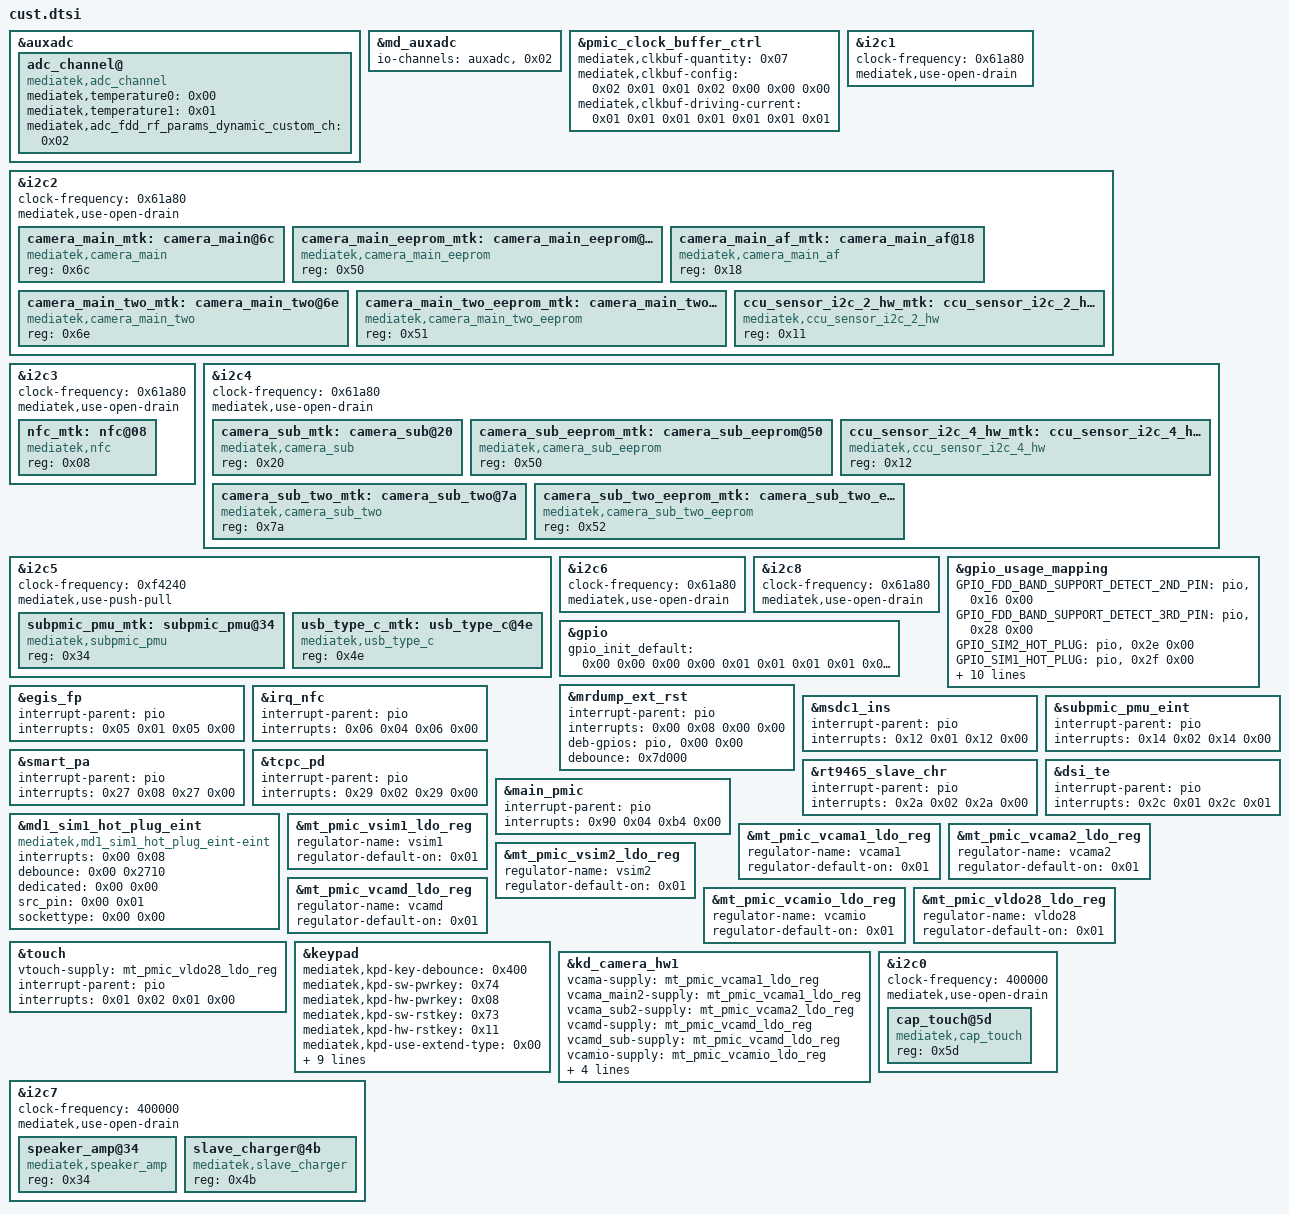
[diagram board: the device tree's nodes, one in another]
/*
 * cust.dtsi - reconstructed from stock dtbo (project 2167A / realme C25s)
 * Generated from stock boot image dtbo.img
 */

&auxadc {

	adc_channel@ {
		compatible = "mediatek,adc_channel";
		mediatek,temperature0 = <0x00>;
		mediatek,temperature1 = <0x01>;
		mediatek,adc_fdd_rf_params_dynamic_custom_ch = <0x02>;
		status = "okay";
	};
};

&md_auxadc {
	io-channels = <&auxadc>, <0x02>;
};

&pmic_clock_buffer_ctrl {
	mediatek,clkbuf-quantity = <0x07>;
	mediatek,clkbuf-config = <0x02 0x01 0x01 0x02 0x00 0x00 0x00>;
	mediatek,clkbuf-driving-current = <0x01 0x01 0x01 0x01 0x01 0x01 0x01>;
	status = "okay";
};

&i2c1 {
	#address-cells = <0x01>;
	#size-cells = <0x00>;
	clock-frequency = <0x61a80>;
	mediatek,use-open-drain;
};

&i2c2 {
	#address-cells = <0x01>;
	#size-cells = <0x00>;
	clock-frequency = <0x61a80>;
	mediatek,use-open-drain;

	camera_main_mtk: camera_main@6c {
		compatible = "mediatek,camera_main";
		reg = <0x6c>;
		status = "okay";
	};

	camera_main_eeprom_mtk: camera_main_eeprom@50 {
		compatible = "mediatek,camera_main_eeprom";
		reg = <0x50>;
		status = "okay";
	};

	camera_main_af_mtk: camera_main_af@18 {
		compatible = "mediatek,camera_main_af";
		reg = <0x18>;
		status = "okay";
	};

	camera_main_two_mtk: camera_main_two@6e {
		compatible = "mediatek,camera_main_two";
		reg = <0x6e>;
		status = "okay";
	};

	camera_main_two_eeprom_mtk: camera_main_two_eeprom@51 {
		compatible = "mediatek,camera_main_two_eeprom";
		reg = <0x51>;
		status = "okay";
	};

	ccu_sensor_i2c_2_hw_mtk: ccu_sensor_i2c_2_hw@11 {
		compatible = "mediatek,ccu_sensor_i2c_2_hw";
		reg = <0x11>;
		status = "okay";
	};
};

&i2c3 {
	#address-cells = <0x01>;
	#size-cells = <0x00>;
	clock-frequency = <0x61a80>;
	mediatek,use-open-drain;

	nfc_mtk: nfc@08 {
		compatible = "mediatek,nfc";
		reg = <0x08>;
		status = "okay";
	};
};

&i2c4 {
	#address-cells = <0x01>;
	#size-cells = <0x00>;
	clock-frequency = <0x61a80>;
	mediatek,use-open-drain;

	camera_sub_mtk: camera_sub@20 {
		compatible = "mediatek,camera_sub";
		reg = <0x20>;
		status = "okay";
	};

	camera_sub_eeprom_mtk: camera_sub_eeprom@50 {
		compatible = "mediatek,camera_sub_eeprom";
		reg = <0x50>;
		status = "okay";
	};

	ccu_sensor_i2c_4_hw_mtk: ccu_sensor_i2c_4_hw@12 {
		compatible = "mediatek,ccu_sensor_i2c_4_hw";
		reg = <0x12>;
		status = "okay";
	};

	camera_sub_two_mtk: camera_sub_two@7a {
		compatible = "mediatek,camera_sub_two";
		reg = <0x7a>;
		status = "okay";
	};

	camera_sub_two_eeprom_mtk: camera_sub_two_eeprom@52 {
		compatible = "mediatek,camera_sub_two_eeprom";
		reg = <0x52>;
		status = "okay";
	};
};

&i2c5 {
	#address-cells = <0x01>;
	#size-cells = <0x00>;
	clock-frequency = <0xf4240>;
	mediatek,use-push-pull;

	subpmic_pmu_mtk: subpmic_pmu@34 {
		compatible = "mediatek,subpmic_pmu";
		reg = <0x34>;
		status = "okay";
	};

	usb_type_c_mtk: usb_type_c@4e {
		compatible = "mediatek,usb_type_c";
		reg = <0x4e>;
		status = "okay";
	};
};

&i2c6 {
	#address-cells = <0x01>;
	#size-cells = <0x00>;
	clock-frequency = <0x61a80>;
	mediatek,use-open-drain;
};

&i2c8 {
	#address-cells = <0x01>;
	#size-cells = <0x00>;
	clock-frequency = <0x61a80>;
	mediatek,use-open-drain;
};

&gpio_usage_mapping {
	GPIO_FDD_BAND_SUPPORT_DETECT_2ND_PIN = <&pio>, <0x16 0x00>;
	GPIO_FDD_BAND_SUPPORT_DETECT_3RD_PIN = <&pio>, <0x28 0x00>;
	GPIO_SIM2_HOT_PLUG = <&pio>, <0x2e 0x00>;
	GPIO_SIM1_HOT_PLUG = <&pio>, <0x2f 0x00>;
	GPIO_FDD_BAND_SUPPORT_DETECT_1ST_PIN = <&pio>, <0x5b 0x00>;
	GPIO_FDD_BAND_SUPPORT_DETECT_4TH_PIN = <&pio>, <0x5c 0x00>;
	GPIO_SIM2_SIO = <&pio>, <0x9b 0x00>;
	GPIO_SIM2_SRST = <&pio>, <0x9c 0x00>;
	GPIO_SIM2_SCLK = <&pio>, <0x9d 0x00>;
	GPIO_SIM1_SCLK = <&pio>, <0xac 0x00>;
	GPIO_SIM1_SRST = <&pio>, <0xad 0x00>;
	GPIO_SIM1_SIO = <&pio>, <0xae 0x00>;
};

&gpio {
	gpio_init_default = <0x00 0x00 0x00 0x00 0x01 0x01 0x01 0x01 0x00 0x00 0x00 0x01 0x01 0x01 0x02 0x00 0x00 0x00 0x01 0x00 0x01 0x03 0x00 0x00 0x00 0x01 0x00 0x01 0x04 0x00 0x01 0x00 0x01 0x00 0x00 0x05 0x00 0x00 0x00 0x01 0x00 0x00 0x06 0x00 0x00 0x00 0x01 0x00 0x00 0x07 0x00 0x00 0x00 0x01 0x00 0x00 0x08 0x07 0x00 0x00 0x01 0x00 0x00 0x09 0x00 0x00 0x00 0x01 0x00 0x00 0x0a 0x00 0x00 0x00 0x01 0x01 0x00 0x0b 0x01 0x00 0x00 0x01 0x00 0x00 0x0c 0x02 0x00 0x00 0x01 0x00 0x00 0x0d 0x02 0x00 0x00 0x01 0x00 0x00 0x0e 0x02 0x01 0x00 0x00 0x00 0x00 0x0f 0x02 0x01 0x00 0x00 0x00 0x00 0x10 0x02 0x01 0x00 0x00 0x00 0x00 0x11 0x00 0x00 0x00 0x00 0x00 0x01 0x12 0x00 0x00 0x00 0x01 0x01 0x01 0x13 0x00 0x01 0x00 0x01 0x00 0x01 0x14 0x00 0x00 0x00 0x00 0x00 0x01 0x15 0x00 0x01 0x00 0x00 0x00 0x00 0x16 0x00 0x00 0x00 0x01 0x00 0x00 0x17 0x00 0x01 0x01 0x00 0x00 0x00 0x18 0x05 0x00 0x00 0x01 0x00 0x00 0x19 0x02 0x01 0x01 0x00 0x00 0x00 0x1a 0x02 0x01 0x00 0x01 0x00 0x00 0x1b 0x02 0x01 0x00 0x00 0x00 0x00 0x1c 0x02 0x00 0x00 0x01 0x00 0x00 0x1d 0x00 0x01 0x00 0x00 0x00 0x00 0x1e 0x00 0x01 0x00 0x00 0x00 0x00 0x1f 0x00 0x00 0x00 0x01 0x00 0x00 0x20 0x07 0x01 0x00 0x00 0x00 0x00 0x21 0x07 0x00 0x00 0x01 0x00 0x00 0x22 0x07 0x00 0x00 0x01 0x00 0x00 0x23 0x07 0x00 0x00 0x01 0x00 0x00 0x24 0x02 0x01 0x00 0x00 0x00 0x00 0x25 0x02 0x01 0x00 0x00 0x00 0x00 0x26 0x00 0x00 0x00 0x01 0x01 0x00 0x27 0x00 0x00 0x00 0x01 0x01 0x01 0x28 0x00 0x00 0x00 0x01 0x00 0x00 0x29 0x00 0x00 0x00 0x01 0x01 0x01 0x2a 0x00 0x00 0x00 0x01 0x01 0x01 0x2b 0x01 0x01 0x00 0x00 0x00 0x00 0x2c 0x01 0x00 0x00 0x01 0x00 0x00 0x2d 0x00 0x01 0x00 0x00 0x00 0x00 0x2e 0x01 0x00 0x00 0x01 0x01 0x00 0x2f 0x01 0x00 0x00 0x01 0x01 0x00 0x30 0x01 0x00 0x00 0x01 0x01 0x01 0x31 0x01 0x00 0x00 0x01 0x01 0x01 0x32 0x01 0x00 0x00 0x01 0x01 0x01 0x33 0x01 0x00 0x00 0x01 0x01 0x01 0x34 0x01 0x00 0x00 0x01 0x00 0x00 0x35 0x00 0x01 0x00 0x00 0x00 0x00 0x36 0x00 0x01 0x00 0x01 0x00 0x00 0x37 0x01 0x00 0x00 0x01 0x00 0x00 0x38 0x01 0x00 0x00 0x01 0x00 0x00 0x39 0x01 0x00 0x00 0x01 0x00 0x00 0x3a 0x00 0x00 0x00 0x01 0x00 0x00 0x3b 0x01 0x00 0x00 0x01 0x00 0x00 0x3c 0x01 0x00 0x00 0x01 0x00 0x00 0x3d 0x01 0x00 0x00 0x01 0x00 0x00 0x3e 0x01 0x00 0x00 0x01 0x00 0x00 0x3f 0x01 0x00 0x00 0x01 0x00 0x00 0x40 0x01 0x00 0x00 0x01 0x00 0x00 0x41 0x01 0x00 0x00 0x01 0x00 0x00 0x42 0x01 0x00 0x00 0x01 0x00 0x00 0x43 0x01 0x00 0x00 0x01 0x00 0x00 0x44 0x01 0x00 0x00 0x01 0x00 0x00 0x45 0x01 0x00 0x00 0x01 0x00 0x00 0x46 0x01 0x00 0x00 0x01 0x00 0x00 0x47 0x01 0x00 0x00 0x01 0x00 0x00 0x48 0x01 0x00 0x00 0x01 0x00 0x00 0x49 0x01 0x00 0x00 0x01 0x00 0x00 0x4a 0x01 0x00 0x00 0x01 0x00 0x00 0x4b 0x01 0x00 0x00 0x01 0x00 0x00 0x4c 0x00 0x00 0x00 0x00 0x00 0x00 0x4d 0x01 0x00 0x00 0x01 0x00 0x00 0x4e 0x01 0x00 0x00 0x01 0x00 0x00 0x4f 0x00 0x00 0x00 0x01 0x00 0x00 0x50 0x00 0x00 0x00 0x01 0x00 0x00 0x51 0x02 0x00 0x00 0x01 0x01 0x01 0x52 0x01 0x00 0x00 0x01 0x01 0x01 0x53 0x01 0x00 0x00 0x01 0x01 0x01 0x54 0x02 0x00 0x00 0x01 0x01 0x01 0x55 0x02 0x00 0x00 0x01 0x00 0x00 0x56 0x02 0x01 0x00 0x00 0x00 0x00 0x57 0x02 0x01 0x00 0x00 0x00 0x00 0x58 0x02 0x01 0x00 0x00 0x00 0x00 0x59 0x01 0x00 0x00 0x01 0x01 0x01 0x5a 0x01 0x00 0x00 0x01 0x01 0x01 0x5b 0x00 0x00 0x00 0x01 0x00 0x00 0x5c 0x00 0x00 0x00 0x01 0x00 0x00 0x5d 0x01 0x00 0x00 0x01 0x01 0x00 0x5e 0x01 0x00 0x00 0x01 0x01 0x00 0x5f 0x01 0x00 0x00 0x01 0x01 0x00 0x60 0x01 0x01 0x00 0x00 0x00 0x00 0x61 0x00 0x01 0x00 0x00 0x00 0x00 0x62 0x00 0x01 0x00 0x00 0x00 0x00 0x63 0x01 0x01 0x00 0x00 0x00 0x00 0x64 0x01 0x01 0x00 0x00 0x00 0x00 0x65 0x00 0x01 0x00 0x00 0x00 0x00 0x66 0x00 0x01 0x00 0x00 0x00 0x00 0x67 0x01 0x00 0x00 0x01 0x01 0x01 0x68 0x01 0x00 0x00 0x01 0x01 0x01 0x69 0x01 0x00 0x00 0x01 0x01 0x01 0x6a 0x01 0x00 0x00 0x01 0x01 0x01 0x6b 0x00 0x01 0x00 0x00 0x00 0x00 0x6c 0x01 0x01 0x00 0x00 0x00 0x00 0x6d 0x00 0x01 0x00 0x00 0x00 0x00 0x6e 0x00 0x01 0x00 0x00 0x00 0x00 0x6f 0x01 0x01 0x00 0x00 0x00 0x00 0x70 0x00 0x01 0x00 0x00 0x00 0x00 0x71 0x00 0x00 0x00 0x01 0x00 0x00 0x72 0x00 0x00 0x00 0x01 0x00 0x00 0x73 0x00 0x00 0x00 0x01 0x00 0x00 0x74 0x00 0x00 0x00 0x01 0x00 0x00 0x75 0x00 0x00 0x00 0x01 0x00 0x00 0x76 0x00 0x00 0x00 0x01 0x00 0x00 0x77 0x00 0x00 0x00 0x01 0x00 0x00 0x78 0x00 0x00 0x00 0x01 0x00 0x00 0x79 0x00 0x00 0x00 0x01 0x00 0x00 0x86 0x01 0x00 0x00 0x01 0x00 0x01 0x87 0x01 0x01 0x00 0x00 0x00 0x00 0x88 0x01 0x01 0x00 0x00 0x00 0x00 0x89 0x01 0x01 0x00 0x00 0x00 0x00 0x8a 0x01 0x01 0x00 0x00 0x00 0x00 0x8b 0x01 0x01 0x00 0x00 0x00 0x00 0x8c 0x01 0x00 0x00 0x01 0x00 0x00 0x8d 0x01 0x00 0x00 0x01 0x00 0x00 0x8e 0x01 0x00 0x00 0x01 0x00 0x00 0x8f 0x01 0x00 0x00 0x01 0x00 0x00 0x90 0x01 0x00 0x00 0x01 0x00 0x00 0x91 0x01 0x01 0x00 0x00 0x00 0x00 0x92 0x01 0x01 0x00 0x00 0x00 0x00 0x93 0x01 0x01 0x00 0x00 0x00 0x00 0x94 0x01 0x01 0x00 0x00 0x00 0x00 0x95 0x01 0x01 0x00 0x00 0x00 0x00 0x96 0x04 0x00 0x00 0x01 0x01 0x00 0x97 0x04 0x01 0x00 0x00 0x00 0x00 0x98 0x00 0x01 0x00 0x01 0x01 0x00 0x99 0x00 0x01 0x00 0x00 0x00 0x00 0x9a 0x01 0x01 0x00 0x00 0x00 0x00 0x9b 0x01 0x00 0x00 0x01 0x01 0x00 0x9c 0x01 0x01 0x00 0x00 0x00 0x00 0x9d 0x01 0x01 0x00 0x00 0x00 0x00 0x9e 0x01 0x01 0x00 0x00 0x00 0x00 0x9f 0x00 0x01 0x00 0x00 0x00 0x00 0xa0 0x00 0x01 0x00 0x00 0x00 0x00 0xa1 0x01 0x00 0x00 0x01 0x01 0x01 0xa2 0x01 0x00 0x00 0x01 0x01 0x01 0xa3 0x01 0x00 0x00 0x01 0x01 0x01 0xa4 0x01 0x00 0x00 0x01 0x01 0x01 0xa5 0x00 0x01 0x00 0x00 0x00 0x00 0xa6 0x00 0x01 0x00 0x00 0x00 0x00 0xa7 0x01 0x00 0x00 0x01 0x00 0x00 0xa8 0x01 0x00 0x00 0x01 0x00 0x00 0xa9 0x00 0x01 0x00 0x00 0x00 0x00 0xaa 0x01 0x00 0x00 0x01 0x01 0x01 0xab 0x01 0x01 0x00 0x00 0x00 0x01 0xac 0x01 0x01 0x00 0x00 0x00 0x00 0xad 0x01 0x01 0x00 0x00 0x00 0x00 0xae 0x01 0x00 0x00 0x01 0x01 0x00 0xaf 0x01 0x00 0x00 0x01 0x01 0x01 0xb0 0x01 0x00 0x00 0x01 0x01 0x01 0xb2 0x00 0x01 0x00 0x00 0x00 0x00 0xb3 0x00 0x01 0x00 0x00 0x00 0x00 0xb4 0x00 0x00 0x00 0x01 0x00 0x00 0xb5 0x00 0x00 0x00 0x01 0x00 0x00 0xb6 0x00 0x00 0x00 0x01 0x00 0x00 0xb7 0x00 0x00 0x00 0x01 0x00 0x00 0xb8 0x00 0x00 0x00 0x01 0x00 0x00 0xb9 0x00 0x00 0x00 0x01 0x00 0x00 0xba 0x00 0x00 0x00 0x01 0x00 0x00>;
};

&mrdump_ext_rst {
	interrupt-parent = <&pio>;
	interrupts = <0x00 0x08 0x00 0x00>;
	deb-gpios = <&pio>, <0x00 0x00>;
	debounce = <0x7d000>;
	status = "okay";
};

&egis_fp {
	interrupt-parent = <&pio>;
	interrupts = <0x05 0x01 0x05 0x00>;
	status = "okay";
};

&irq_nfc {
	interrupt-parent = <&pio>;
	interrupts = <0x06 0x04 0x06 0x00>;
	status = "okay";
};

&msdc1_ins {
	interrupt-parent = <&pio>;
	interrupts = <0x12 0x01 0x12 0x00>;
	status = "okay";
};

&subpmic_pmu_eint {
	interrupt-parent = <&pio>;
	interrupts = <0x14 0x02 0x14 0x00>;
	status = "okay";
};

&smart_pa {
	interrupt-parent = <&pio>;
	interrupts = <0x27 0x08 0x27 0x00>;
	status = "okay";
};

&tcpc_pd {
	interrupt-parent = <&pio>;
	interrupts = <0x29 0x02 0x29 0x00>;
	status = "okay";
};

&rt9465_slave_chr {
	interrupt-parent = <&pio>;
	interrupts = <0x2a 0x02 0x2a 0x00>;
	status = "okay";
};

&dsi_te {
	interrupt-parent = <&pio>;
	interrupts = <0x2c 0x01 0x2c 0x01>;
	status = "okay";
};

&main_pmic {
	interrupt-parent = <&pio>;
	interrupts = <0x90 0x04 0xb4 0x00>;
	status = "okay";
};

&md1_sim1_hot_plug_eint {
	compatible = "mediatek,md1_sim1_hot_plug_eint-eint";
	interrupts = <0x00 0x08>;
	debounce = <0x00 0x2710>;
	dedicated = <0x00 0x00>;
	src_pin = <0x00 0x01>;
	sockettype = <0x00 0x00>;
	status = "okay";
};

&mt_pmic_vcama1_ldo_reg {
	regulator-name = "vcama1";
	regulator-default-on = <0x01>;
	status = "okay";
};

&mt_pmic_vcama2_ldo_reg {
	regulator-name = "vcama2";
	regulator-default-on = <0x01>;
	status = "okay";
};

&mt_pmic_vsim1_ldo_reg {
	regulator-name = "vsim1";
	regulator-default-on = <0x01>;
	status = "okay";
};

&mt_pmic_vsim2_ldo_reg {
	regulator-name = "vsim2";
	regulator-default-on = <0x01>;
	status = "okay";
};

&mt_pmic_vcamd_ldo_reg {
	regulator-name = "vcamd";
	regulator-default-on = <0x01>;
	status = "okay";
};

&mt_pmic_vcamio_ldo_reg {
	regulator-name = "vcamio";
	regulator-default-on = <0x01>;
	status = "okay";
};

&mt_pmic_vldo28_ldo_reg {
	regulator-name = "vldo28";
	regulator-default-on = <0x01>;
	status = "okay";
};

&touch {
	vtouch-supply = <&mt_pmic_vldo28_ldo_reg>;
	status = "okay";
};

&touch {
	interrupt-parent = <&pio>;
	interrupts = <0x01 0x02 0x01 0x00>;
	status = "okay";
};

&keypad {
	mediatek,kpd-key-debounce = <0x400>;
	mediatek,kpd-sw-pwrkey = <0x74>;
	mediatek,kpd-hw-pwrkey = <0x08>;
	mediatek,kpd-sw-rstkey = <0x73>;
	mediatek,kpd-hw-rstkey = <0x11>;
	mediatek,kpd-use-extend-type = <0x00>;
	mediatek,kpd-hw-map-num = <0x48>;
	mediatek,kpd-hw-init-map = <0x00 0x72 0x00 0x00 0x00 0x00 0x00 0x00 0x00 0x00 0x00 0x00 0x00 0x00 0x00 0x00 0x00 0x00 0x00 0x00 0x00 0x00 0x00 0x00 0x00 0x00 0x00 0x00 0x00 0x00 0x00 0x00 0x00 0x00 0x00 0x00 0x00 0x00 0x00 0x00 0x00 0x00 0x00 0x00 0x00 0x00 0x00 0x00 0x00 0x00 0x00 0x00 0x00 0x00 0x00 0x00 0x00 0x00 0x00 0x00 0x00 0x00 0x00 0x00 0x00 0x00 0x00 0x00 0x00 0x00 0x00 0x00>;
	mediatek,kpd-pwrkey-eint-gpio = <0x00>;
	mediatek,kpd-pwkey-gpio-din = <0x00>;
	mediatek,kpd-hw-dl-key0 = <0x11>;
	mediatek,kpd-hw-dl-key1 = <0x01>;
	mediatek,kpd-hw-recovery-key = <0x01>;
	mediatek,kpd-hw-factory-key = <0x11>;
	status = "okay";
};

&kd_camera_hw1 {
	vcama-supply = <&mt_pmic_vcama1_ldo_reg>;
	vcama_main2-supply = <&mt_pmic_vcama1_ldo_reg>;
	vcama_sub2-supply = <&mt_pmic_vcama2_ldo_reg>;
	vcamd-supply = <&mt_pmic_vcamd_ldo_reg>;
	vcamd_sub-supply = <&mt_pmic_vcamd_ldo_reg>;
	vcamio-supply = <&mt_pmic_vcamio_ldo_reg>;
	vcamio_sub-supply = <&mt_pmic_vcamio_ldo_reg>;
	vcamio_main2-supply = <&mt_pmic_vcamio_ldo_reg>;
	vcamio_sub2-supply = <&mt_pmic_vcamio_ldo_reg>;
	vcamaf-supply = <&mt_pmic_vldo28_ldo_reg>;
	status = "okay";
};

&i2c0 {
	#address-cells = <1>;
	#size-cells = <0>;
	clock-frequency = <400000>;
	mediatek,use-open-drain;

	cap_touch@5d {
		compatible = "mediatek,cap_touch";
		reg = <0x5d>;
		status = "okay";
	};
};

&i2c7 {
	#address-cells = <1>;
	#size-cells = <0>;
	clock-frequency = <400000>;
	mediatek,use-open-drain;

	speaker_amp@34 {
		compatible = "mediatek,speaker_amp";
		reg = <0x34>;
		status = "okay";
	};

	slave_charger@4b {
		compatible = "mediatek,slave_charger";
		reg = <0x4b>;
		status = "okay";
	};
};
